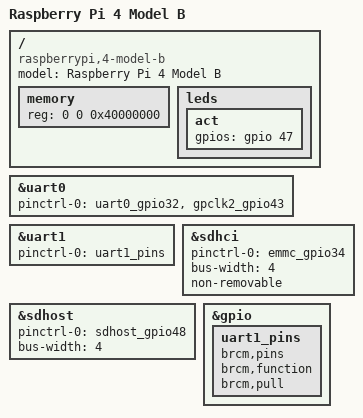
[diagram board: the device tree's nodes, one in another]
/dts-v1/;
#include "bcm2838.dtsi"

/ {
	compatible = "raspberrypi,4-model-b","brcm,bcm2838","brcm,bcm2837";
	model = "Raspberry Pi 4 Model B";

	memory {
		reg = <0 0 0x40000000>;
	};

	leds {
		act {
			gpios = <&gpio 47 0>;
		};
	};
};

/* uart0 communicates with the BT module */
&uart0 {
	pinctrl-names = "default";
	pinctrl-0 = <&uart0_gpio32 &gpclk2_gpio43>;
	status = "okay";
};

/* uart1 is mapped to the pin header */
&uart1 {
	pinctrl-names = "default";
	pinctrl-0 = <&uart1_pins>;
	status = "okay";
};

/* SDHCI is used to control the SDIO for wireless */
&sdhci {
	pinctrl-names = "default";
	pinctrl-0 = <&emmc_gpio34>;
	status = "okay";
	bus-width = <4>;
	non-removable;
};

/* SDHOST is used to drive the SD card */
&sdhost {
	pinctrl-names = "default";
	pinctrl-0 = <&sdhost_gpio48>;
	status = "okay";
	bus-width = <4>;
};

&gpio {
	uart1_pins: uart1_pins {
		brcm,pins;
		brcm,function;
		brcm,pull;
	};
};
